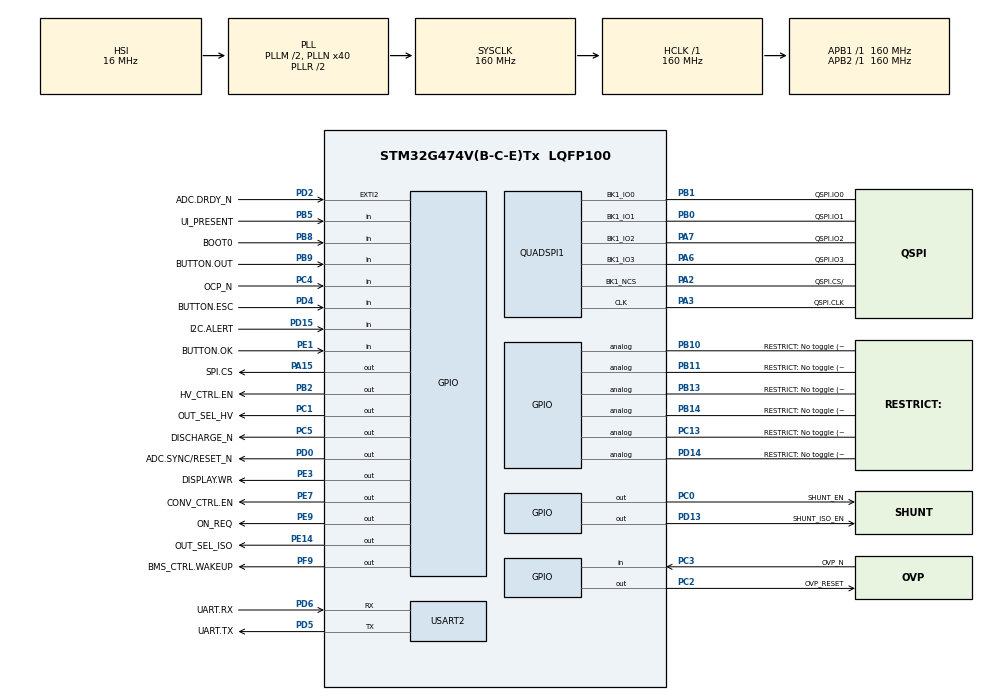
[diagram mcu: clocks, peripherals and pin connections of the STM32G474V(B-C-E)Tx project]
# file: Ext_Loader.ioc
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Mcu.Family=STM32G4
Mcu.Name=STM32G474V(B-C-E)Tx
Mcu.Package=LQFP100
NVIC.EXTI2_IRQn=true\:0\:0\:false\:false\:true\:true\:true\:false
NVIC.PriorityGroup=NVIC_PRIORITYGROUP_4
PA0.GPIO_Label=I_OUT
PA0.Signal=ADC1_IN1
PA1.GPIO_Label=V_TERM
PA1.Signal=ADC2_IN2
PA10.GPIO_Label=CONV_CTRL.PRIM_L
PA10.Signal=HRTIM1_CHB1
PA11.GPIO_Label=CONV_CTRL.PRIM_H
PA11.Signal=HRTIM1_CHB2
PA12.GPIO_Label=ADC.CLK
PA12.GPIO_Speed=GPIO_SPEED_FREQ_VERY_HIGH
PA12.Signal=S_TIM16_CH1
PA13.GPIO_Label=SWD.SWDAT
PA13.Mode=Trace_Asynchronous_SW
PA13.Signal=SYS_JTMS-SWDIO
PA14.GPIO_Label=SWD.SWCLK
PA14.Mode=Trace_Asynchronous_SW
PA14.Signal=SYS_JTCK-SWCLK
PA15.GPIO_Label=SPI.CS
PA15.GPIO_Speed=GPIO_SPEED_FREQ_VERY_HIGH
PA15.Signal=GPIO_Output
PA2.GPIO_Label=QSPI.CS/
PA2.GPIO_Speed=GPIO_SPEED_FREQ_VERY_HIGH
PA2.Mode=Single Bank 1
PA2.Signal=QUADSPI1_BK1_NCS
PA3.GPIO_Label=QSPI.CLK
PA3.GPIO_Speed=GPIO_SPEED_FREQ_VERY_HIGH
PA3.Mode=Single Bank 1
PA3.Signal=QUADSPI1_CLK
PA4.GPIO_Label=VREF/2_UC
PA4.Signal=COMP_DAC11_group
PA5.GPIO_Label=I_1A_REF
PA5.Signal=COMP_DAC12_group
PA6.GPIO_Label=QSPI.IO3
PA6.GPIO_Speed=GPIO_SPEED_FREQ_VERY_HIGH
PA6.Mode=Single Bank 1
PA6.Signal=QUADSPI1_BK1_IO3
PA7.GPIO_Label=QSPI.IO2
PA7.GPIO_Speed=GPIO_SPEED_FREQ_VERY_HIGH
PA7.Mode=Single Bank 1
PA7.Signal=QUADSPI1_BK1_IO2
PA8.GPIO_Label=BMS_CTRL.I_BAT
PA8.Signal=ADC5_IN1
PA9.GPIO_Label=I_ISO
PA9.Signal=ADC5_IN2
PB0.GPIO_Label=QSPI.IO1
PB0.GPIO_Speed=GPIO_SPEED_FREQ_VERY_HIGH
PB0.Mode=Single Bank 1
PB0.Signal=QUADSPI1_BK1_IO1
PB1.GPIO_Label=QSPI.IO0
PB1.GPIO_Speed=GPIO_SPEED_FREQ_VERY_HIGH
PB1.Mode=Single Bank 1
PB1.Signal=QUADSPI1_BK1_IO0
PB10.GPIO_Label=RESTRICT\: No toggle (REFBUF)
PB10.Signal=GPIO_Analog
PB11.GPIO_Label=RESTRICT\: No toggle (REFBUF)
PB11.Signal=GPIO_Analog
PB12.GPIO_Label=HV_CTRL.PRIM
PB12.Signal=HRTIM1_CHC1
PB13.GPIO_Label=RESTRICT\: No toggle (REFBUF)
PB13.Signal=GPIO_Analog
PB14.GPIO_Label=RESTRICT\: No toggle (REFBUF)
PB14.Signal=GPIO_Analog
PB2.GPIO_Label=HV_CTRL.EN
PB2.Signal=GPIO_Output
PB3.GPIO_Label=SWD.SWO
PB3.Mode=Trace_Asynchronous_SW
PB3.Signal=SYS_JTDO-SWO
PB5.GPIO_Label=UI_PRESENT
PB5.Signal=GPIO_Input
PB6.GPIO_Label=ENCODER.B
PB6.Signal=S_TIM4_CH1
PB7.GPIO_Label=ENCODER.A
PB7.Signal=S_TIM4_CH2
PB8-BOOT0.GPIO_Label=BOOT0
PB8-BOOT0.Signal=GPIO_Input
PB9.GPIO_Label=BUTTON.OUT
PB9.Signal=GPIO_Input
PC0.GPIO_Label=SHUNT_EN
PC0.PinState=GPIO_PIN_SET
PC0.Signal=GPIO_Output
PC1.GPIO_Label=OUT_SEL_HV
PC1.Signal=GPIO_Output
PC10.GPIO_Label=SPI.SCK
PC10.GPIO_Speed=GPIO_SPEED_FREQ_VERY_HIGH
PC10.Signal=SPI3_SCK
PC11.GPIO_Label=SPI.MISO
PC11.GPIO_Speed=GPIO_SPEED_FREQ_VERY_HIGH
PC11.Signal=SPI3_MISO
PC12.GPIO_Label=SPI.MOSI
PC12.GPIO_Speed=GPIO_SPEED_FREQ_VERY_HIGH
PC12.Signal=SPI3_MOSI
PC13.GPIO_Label=RESTRICT\: No toggle (LSE)
PC13.Signal=GPIO_Analog
PC14-OSC32_IN.Signal=RCC_OSC32_IN
PC15-OSC32_OUT.Signal=RCC_OSC32_OUT
PC2.GPIO_Label=OVP_RESET
PC2.Signal=GPIO_Output
PC3.GPIO_Label=OVP_N
PC3.Signal=GPIO_Input
PC4.GPIO_Label=OCP_N
PC4.Signal=GPIO_Input
PC5.GPIO_Label=DISCHARGE_N
PC5.PinState=GPIO_PIN_SET
PC5.Signal=GPIO_Output
PC8.GPIO_Label=CONV_CTRL.SEC_L
PC8.Signal=HRTIM1_CHE1
PC9.GPIO_Label=CONV_CTRL.SEC_H
PC9.Signal=HRTIM1_CHE2
PD0.GPIO_Label=ADC.SYNC/RESET_N
PD0.GPIO_Speed=GPIO_SPEED_FREQ_HIGH
PD0.Signal=GPIO_Output
PD10.GPIO_Label=CONV_CTRL.TEMP_SEC
PD10.Signal=ADC5_IN7
PD11.GPIO_Label=V_3V3_A
PD11.Signal=ADC5_IN8
PD12.GPIO_Label=CONV_CTRL.TEMP_TRAFO
PD12.Signal=ADC5_IN9
PD13.GPIO_Label=SHUNT_ISO_EN
PD13.Signal=GPIO_Output
PD14.GPIO_Label=RESTRICT\: No toggle (REFBUF)
PD14.Signal=GPIO_Analog
PD15.GPIO_Label=I2C.ALERT
PD15.Signal=GPIO_Input
PD2.GPIO_Label=ADC.DRDY_N
PD2.GPIO_ModeDefaultEXTI=GPIO_MODE_IT_FALLING
PD2.Signal=GPXTI2
PD4.GPIO_Label=BUTTON.ESC
PD4.Signal=GPIO_Input
PD5.GPIO_Label=UART.TX
PD5.Mode=Asynchronous
PD5.Signal=USART2_TX
PD6.GPIO_Label=UART.RX
PD6.Mode=Asynchronous
PD6.Signal=USART2_RX
PD8.GPIO_Label=TEMP_CURRENT
PD8.Signal=ADC5_IN12
PD9.GPIO_Label=CONV_CTRL.TEMP_PRIM
PD9.Signal=ADC5_IN13
PE1.GPIO_Label=BUTTON.OK
PE1.Signal=GPIO_Input
PE10.GPIO_Label=V_15V
PE10.Signal=ADC5_IN14
PE11.GPIO_Label=V_VCC
PE11.Signal=ADC5_IN15
PE12.GPIO_Label=V_5V
PE12.Signal=ADC5_IN16
PE13.GPIO_Label=V_IN
PE13.Signal=ADC3_IN3
PE14.GPIO_Label=OUT_SEL_ISO
PE14.Signal=GPIO_Output
PE15.GPIO_Label=V_OUT
PE15.Signal=ADC4_IN2
PE2.GPIO_Label=DISPLAY.SCK
PE2.GPIO_Speed=GPIO_SPEED_FREQ_VERY_HIGH
PE2.Signal=SPI4_SCK
PE3.GPIO_Label=DISPLAY.WR
PE3.GPIO_Speed=GPIO_SPEED_FREQ_VERY_HIGH
PE3.Signal=GPIO_Output
PE4.GPIO_Label=DISPLAY.CS
PE4.GPIO_Speed=GPIO_SPEED_FREQ_VERY_HIGH
PE4.Signal=SPI4_NSS
PE5.GPIO_Label=DISPLAY.MISO
PE5.GPIO_Speed=GPIO_SPEED_FREQ_VERY_HIGH
PE5.Signal=SPI4_MISO
PE6.GPIO_Label=DISPLAY.MOSI
PE6.GPIO_Speed=GPIO_SPEED_FREQ_VERY_HIGH
PE6.Signal=SPI4_MOSI
PE7.GPIO_Label=CONV_CTRL.EN
PE7.Signal=GPIO_Output
PE8.GPIO_Label=V_3V3
PE8.Signal=ADC5_IN6
PE9.GPIO_Label=ON_REQ
PE9.PinState=GPIO_PIN_SET
PE9.Signal=GPIO_Output
PF9.GPIO_Label=BMS_CTRL.WAKEUP
PF9.Signal=GPIO_Output
ProjectManager.HeapSize=0x200
ProjectManager.StackSize=0x400
ProjectManager.TargetToolchain=STM32CubeIDE
QUADSPI1.ChipSelectHighTime=QSPI_CS_HIGH_TIME_4_CYCLE
QUADSPI1.ClockMode=QSPI_CLOCK_MODE_3
QUADSPI1.ClockPrescaler=1
QUADSPI1.FlashSize=26
RCC.ADC12Freq_Value=160000000
RCC.ADC345Freq_Value=160000000
RCC.AHBFreq_Value=160000000
RCC.APB1Freq_Value=160000000
RCC.APB1TimFreq_Value=160000000
RCC.APB2Freq_Value=160000000
RCC.APB2TimFreq_Value=160000000
RCC.CortexFreq_Value=160000000
RCC.EXTERNAL_CLOCK_VALUE=12288000
RCC.HCLKFreq_Value=160000000
RCC.HSE_VALUE=8000000
RCC.HSI48_VALUE=48000000
RCC.HSI_VALUE=16000000
RCC.LSE_VALUE=32768
RCC.PLLM=RCC_PLLM_DIV2
RCC.PLLN=40
RCC.RTCClockSelection=RCC_RTCCLKSOURCE_LSE
RCC.SYSCLKFreq_VALUE=160000000
RCC.SYSCLKSource=RCC_SYSCLKSOURCE_PLLCLK
RCC.USBFreq_Value=160000000
RCC.VCOOutputFreq_Value=320000000
SH.COMP_DAC11_group.0=DAC1_OUT1
SH.COMP_DAC12_group.0=DAC1_OUT2
SH.S_TIM16_CH1.0=TIM16_CH1
SH.S_TIM4_CH1.0=TIM4_CH1
SH.S_TIM4_CH2.0=TIM4_CH2
SYS.VoltageScaling=SYSCFG_VREFBUF_VOLTAGE_SCALE1
USART2.FIFOMode=FIFOMODE_ENABLE
USART2.VirtualMode-Asynchronous=VM_ASYNC
VP_SYS_VS_DBSignals.Mode=DisableDeadBatterySignals
VREF+.GPIO_Label=VREF_UC
VREF+.Mode=InternalMode
VREF+.Signal=VREFBUF_OUT
board=custom

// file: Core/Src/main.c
/* USER CODE BEGIN Header */
/**
  ******************************************************************************
  * @file           : main.c
  * @brief          : Main program body
  ******************************************************************************
  * @attention
  *
  * Copyright (c) 2026 STMicroelectronics.
  * All rights reserved.
  *
  * This software is licensed under terms that can be found in the LICENSE file
  * in the root directory of this software component.
  * If no LICENSE file comes with this software, it is provided AS-IS.
  *
  ******************************************************************************
  */
/* USER CODE END Header */
#include "main.h"
#include "quadspi.h"
#include "usart.h"
#include "gpio.h"

/* USER CODE BEGIN Includes */
#include "w25n01gv.h"
#include "Loader_Src.h"
#include "cli.h"
/* USER CODE END Includes */

/* USER CODE BEGIN PV */
w25n01gv_handle flash;
w25n01gv_status_t flash_status = W25N01GV_OK;

/* USER CODE END PV */

void SystemClock_Config(void);

int main(void)
{

  /* MCU Configuration--------------------------------------------------------*/

  /* Reset of all peripherals, Initializes the Flash interface and the Systick. */
  HAL_Init();

  /* Configure the system clock */
  SystemClock_Config();

  /* Initialize all configured peripherals */
  MX_GPIO_Init();
  MX_QUADSPI1_Init();
  MX_USART2_UART_Init();
  /* USER CODE BEGIN 2 */

  /*
   * CLI Setup
   */
  cli_init(&huart2);

  /*
   * QSPI flash memory init
   */
  flash_status = w25n01gv_init(&flash, &hqspi1, 1000);
/*  if (flash_status == HAL_OK){
    flash_status = w25n01gv_wait_busy(&flash);
  }
  if (flash_status == HAL_OK){
  	flash_status = w25n01gv_buffer_mode_disable(&flash);
  }
  if (flash_status == HAL_OK){
    flash_status = w25n01gv_wait_busy(&flash);
  }*/
/*  if (flash_status != W25N01GV_OK) {
    printf("Flash initialisation failed!\r\n");
  }*/

//  Init();
//  Write(0, 0, 0);
//  SectorErase(0, 0);
//  Read(0, 0, 0);
//  //Verify(0, 0, 0);
//  MassErase();
//  //Checksum(); // Todo: Parameters not specified in documentation

  gpio_turnOn();

  /* USER CODE END 2 */

  /* Infinite loop */
  /* USER CODE BEGIN WHILE */
  while (1)
  {
    cli_loop();

    HAL_Delay(1);
    /* USER CODE END WHILE */

  }
}

void SystemClock_Config(void)
{
  RCC_OscInitTypeDef RCC_OscInitStruct = {0};
  RCC_ClkInitTypeDef RCC_ClkInitStruct = {0};

  /** Configure the main internal regulator output voltage
  */
  HAL_PWREx_ControlVoltageScaling(PWR_REGULATOR_VOLTAGE_SCALE1_BOOST);

  /** Initializes the RCC Oscillators according to the specified parameters
  * in the RCC_OscInitTypeDef structure.
  */
  RCC_OscInitStruct.OscillatorType = RCC_OSCILLATORTYPE_HSI;
  RCC_OscInitStruct.HSIState = RCC_HSI_ON;
  RCC_OscInitStruct.HSICalibrationValue = RCC_HSICALIBRATION_DEFAULT;
  RCC_OscInitStruct.PLL.PLLState = RCC_PLL_ON;
  RCC_OscInitStruct.PLL.PLLSource = RCC_PLLSOURCE_HSI;
  RCC_OscInitStruct.PLL.PLLM = RCC_PLLM_DIV2;
  RCC_OscInitStruct.PLL.PLLN = 40;
  RCC_OscInitStruct.PLL.PLLP = RCC_PLLP_DIV2;
  RCC_OscInitStruct.PLL.PLLQ = RCC_PLLQ_DIV2;
  RCC_OscInitStruct.PLL.PLLR = RCC_PLLR_DIV2;
  if (HAL_RCC_OscConfig(&RCC_OscInitStruct) != HAL_OK)
  {
    Error_Handler();
  }

  /** Initializes the CPU, AHB and APB buses clocks
  */
  RCC_ClkInitStruct.ClockType = RCC_CLOCKTYPE_HCLK|RCC_CLOCKTYPE_SYSCLK
                              |RCC_CLOCKTYPE_PCLK1|RCC_CLOCKTYPE_PCLK2;
  RCC_ClkInitStruct.SYSCLKSource = RCC_SYSCLKSOURCE_PLLCLK;
  RCC_ClkInitStruct.AHBCLKDivider = RCC_SYSCLK_DIV1;
  RCC_ClkInitStruct.APB1CLKDivider = RCC_HCLK_DIV1;
  RCC_ClkInitStruct.APB2CLKDivider = RCC_HCLK_DIV1;

  if (HAL_RCC_ClockConfig(&RCC_ClkInitStruct, FLASH_LATENCY_4) != HAL_OK)
  {
    Error_Handler();
  }
}

/* USER CODE BEGIN 4 */
/**
 * External ADC finished SPI communication
 */
//void HAL_SPI_TxRxCpltCallback(SPI_HandleTypeDef *hspi) {
//	return;
//}

/**
 * Interrupt for external ADC
 */
//void HAL_GPIO_EXTI_Callback(uint16_t GPIO_Pin) {
//	return;
//}
/* USER CODE END 4 */

void Error_Handler(void)
{
  __disable_irq();
  while (1)
  {
  }
}
